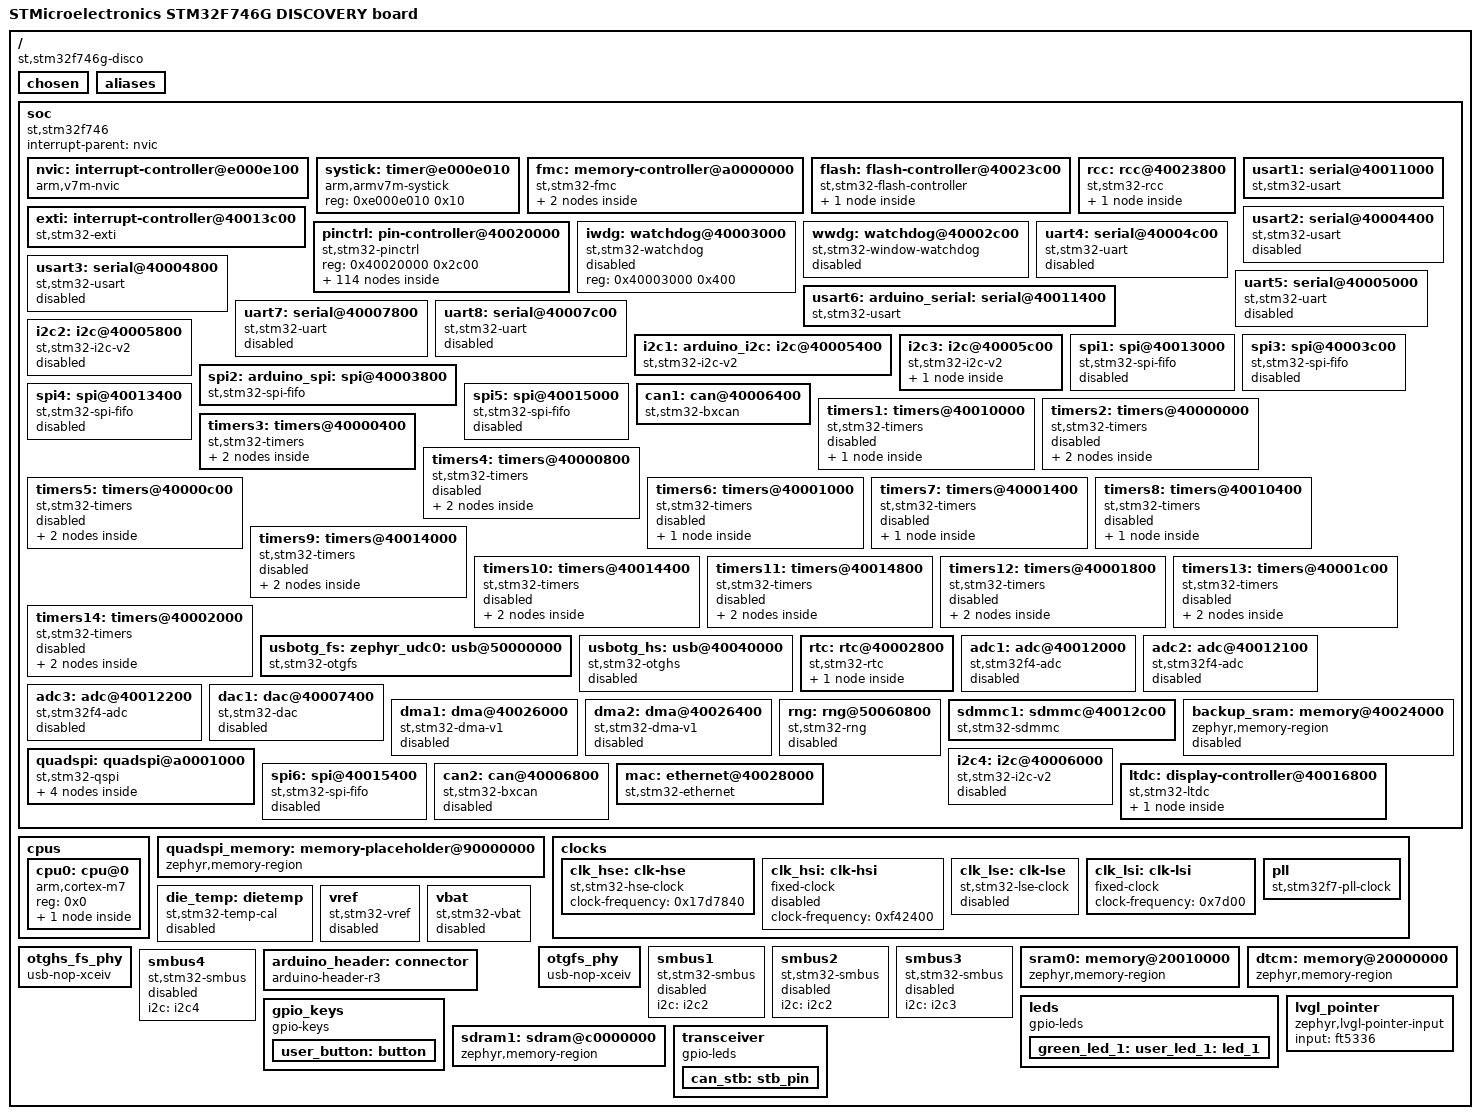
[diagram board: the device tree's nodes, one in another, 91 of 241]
/dts-v1/;

/ {
	#address-cells = < 0x1 >;
	#size-cells = < 0x1 >;
	model = "STMicroelectronics STM32F746G DISCOVERY board";
	compatible = "st,stm32f746g-disco";
	chosen {
		zephyr,entropy = &rng;
		zephyr,flash-controller = &n25q128a1;
		zephyr,console = &usart1;
		zephyr,shell-uart = &usart1;
		zephyr,sram = &sram0;
		zephyr,flash = &flash0;
		zephyr,dtcm = &dtcm;
		zephyr,display = &ltdc;
	};
	aliases {
		led0 = &green_led_1;
		sw0 = &user_button;
		can-primary = &can1;
		led-warn = &user_led_1;
	};
	soc {
		#address-cells = < 0x1 >;
		#size-cells = < 0x1 >;
		compatible = "st,stm32f746", "st,stm32f7", "simple-bus";
		interrupt-parent = < &nvic >;
		ranges;
		nvic: interrupt-controller@e000e100 {
			#address-cells = < 0x1 >;
			compatible = "arm,v7m-nvic";
			reg = < 0xe000e100 0xc00 >;
			interrupt-controller;
			#interrupt-cells = < 0x2 >;
			arm,num-irq-priority-bits = < 0x4 >;
			phandle = < 0x1 >;
		};
		systick: timer@e000e010 {
			compatible = "arm,armv7m-systick";
			reg = < 0xe000e010 0x10 >;
		};
		fmc: memory-controller@a0000000 {
			compatible = "st,stm32-fmc";
			reg = < 0xa0000000 0x400 >;
			clocks = < &rcc 0x38 0x1 >;
			status = "okay";
			pinctrl-0 = < &fmc_nbl0_pe0 &fmc_nbl1_pe1 &fmc_sdclk_pg8 &fmc_sdnwe_ph5 &fmc_sdcke0_pc3 &fmc_sdne0_ph3 &fmc_sdnras_pf11 &fmc_sdncas_pg15 &fmc_a0_pf0 &fmc_a1_pf1 &fmc_a2_pf2 &fmc_a3_pf3 &fmc_a4_pf4 &fmc_a5_pf5 &fmc_a6_pf12 &fmc_a7_pf13 &fmc_a8_pf14 &fmc_a9_pf15 &fmc_a10_pg0 &fmc_a11_pg1 &fmc_a14_pg4 &fmc_a15_pg5 &fmc_d0_pd14 &fmc_d1_pd15 &fmc_d2_pd0 &fmc_d3_pd1 &fmc_d4_pe7 &fmc_d5_pe8 &fmc_d6_pe9 &fmc_d7_pe10 &fmc_d8_pe11 &fmc_d9_pe12 &fmc_d10_pe13 &fmc_d11_pe14 &fmc_d12_pe15 &fmc_d13_pd8 &fmc_d14_pd9 &fmc_d15_pd10 >;
			pinctrl-names = "default";
			sdram: sdram {
				compatible = "st,stm32-fmc-sdram";
				#address-cells = < 0x1 >;
				#size-cells = < 0x0 >;
				status = "okay";
				power-up-delay = < 0x64 >;
				num-auto-refresh = < 0x8 >;
				mode-register = < 0x220 >;
				refresh-rate = < 0x683 >;
				bank@0 {
					reg = < 0x0 >;
					st,sdram-control = < 0x0 0x4 0x10 0x40 0x100 0x800 0x1000 0x0 >;
					st,sdram-timing = < 0x2 0x6 0x4 0x6 0x2 0x2 0x2 >;
				};
			};
		};
		flash: flash-controller@40023c00 {
			compatible = "st,stm32-flash-controller", "st,stm32f7-flash-controller";
			reg = < 0x40023c00 0x400 >;
			interrupts = < 0x4 0x0 >;
			#address-cells = < 0x1 >;
			#size-cells = < 0x1 >;
			flash0: flash@8000000 {
				compatible = "st,stm32-nv-flash", "soc-nv-flash";
				write-block-size = < 0x1 >;
				max-erase-time = < 0xfa0 >;
				reg = < 0x8000000 0x100000 >;
			};
		};
		rcc: rcc@40023800 {
			compatible = "st,stm32-rcc";
			#clock-cells = < 0x2 >;
			reg = < 0x40023800 0x400 >;
			clocks = < &pll >;
			clock-frequency = < 0xcdfe600 >;
			ahb-prescaler = < 0x1 >;
			apb1-prescaler = < 0x4 >;
			apb2-prescaler = < 0x2 >;
			phandle = < 0x2 >;
			rctl: reset-controller {
				compatible = "st,stm32-rcc-rctl";
				#reset-cells = < 0x1 >;
				phandle = < 0x2a >;
			};
		};
		exti: interrupt-controller@40013c00 {
			compatible = "st,stm32-exti";
			interrupt-controller;
			#interrupt-cells = < 0x1 >;
			#address-cells = < 0x1 >;
			reg = < 0x40013c00 0x400 >;
			num-lines = < 0x10 >;
			interrupts = < 0x6 0x0 >, < 0x7 0x0 >, < 0x8 0x0 >, < 0x9 0x0 >, < 0xa 0x0 >, < 0x17 0x0 >, < 0x28 0x0 >;
			interrupt-names = "line0", "line1", "line2", "line3", "line4", "line5-9", "line10-15";
			line-ranges = < 0x0 0x1 >, < 0x1 0x1 >, < 0x2 0x1 >, < 0x3 0x1 >, < 0x4 0x1 >, < 0x5 0x5 >, < 0xa 0x6 >;
		};
		pinctrl: pin-controller@40020000 {
			compatible = "st,stm32-pinctrl";
			#address-cells = < 0x1 >;
			#size-cells = < 0x1 >;
			reg = < 0x40020000 0x2c00 >;
			gpioa: gpio@40020000 {
				compatible = "st,stm32-gpio";
				gpio-controller;
				#gpio-cells = < 0x2 >;
				reg = < 0x40020000 0x400 >;
				clocks = < &rcc 0x30 0x1 >;
				phandle = < 0x37 >;
			};
			gpiob: gpio@40020400 {
				compatible = "st,stm32-gpio";
				gpio-controller;
				#gpio-cells = < 0x2 >;
				reg = < 0x40020400 0x400 >;
				clocks = < &rcc 0x30 0x2 >;
				phandle = < 0x7a >;
			};
			gpioc: gpio@40020800 {
				compatible = "st,stm32-gpio";
				gpio-controller;
				#gpio-cells = < 0x2 >;
				reg = < 0x40020800 0x400 >;
				clocks = < &rcc 0x30 0x4 >;
				phandle = < 0x45 >;
			};
			gpiod: gpio@40020C00 {
				compatible = "st,stm32-gpio";
				gpio-controller;
				#gpio-cells = < 0x2 >;
				reg = < 0x40020c00 0x400 >;
				clocks = < &rcc 0x30 0x8 >;
			};
			gpioe: gpio@40021000 {
				compatible = "st,stm32-gpio";
				gpio-controller;
				#gpio-cells = < 0x2 >;
				reg = < 0x40021000 0x400 >;
				clocks = < &rcc 0x30 0x10 >;
			};
			gpiof: gpio@40021400 {
				compatible = "st,stm32-gpio";
				gpio-controller;
				#gpio-cells = < 0x2 >;
				reg = < 0x40021400 0x400 >;
				clocks = < &rcc 0x30 0x20 >;
				phandle = < 0x78 >;
			};
			gpiog: gpio@40021800 {
				compatible = "st,stm32-gpio";
				gpio-controller;
				#gpio-cells = < 0x2 >;
				reg = < 0x40021800 0x400 >;
				clocks = < &rcc 0x30 0x40 >;
				phandle = < 0x79 >;
			};
			gpioh: gpio@40021C00 {
				compatible = "st,stm32-gpio";
				gpio-controller;
				#gpio-cells = < 0x2 >;
				reg = < 0x40021c00 0x400 >;
				clocks = < &rcc 0x30 0x80 >;
				phandle = < 0x7b >;
			};
			gpioi: gpio@40022000 {
				compatible = "st,stm32-gpio";
				gpio-controller;
				#gpio-cells = < 0x2 >;
				reg = < 0x40022000 0x400 >;
				clocks = < &rcc 0x30 0x100 >;
				phandle = < 0x33 >;
			};
			gpioj: gpio@40022400 {
				compatible = "st,stm32-gpio";
				gpio-controller;
				#gpio-cells = < 0x2 >;
				reg = < 0x40022400 0x400 >;
				clocks = < &rcc 0x30 0x200 >;
			};
			gpiok: gpio@40022800 {
				compatible = "st,stm32-gpio";
				gpio-controller;
				#gpio-cells = < 0x2 >;
				reg = < 0x40022800 0x400 >;
				clocks = < &rcc 0x30 0x400 >;
				phandle = < 0x71 >;
			};
			can1_rx_pb8: can1_rx_pb8 {
				pinmux = < 0x309 >;
				bias-pull-up;
				phandle = < 0x38 >;
			};
			can1_tx_pb9: can1_tx_pb9 {
				pinmux = < 0x329 >;
				phandle = < 0x39 >;
			};
			eth_crs_dv_pa7: eth_crs_dv_pa7 {
				pinmux = < 0xeb >;
				slew-rate = "very-high-speed";
				phandle = < 0x51 >;
			};
			eth_mdc_pc1: eth_mdc_pc1 {
				pinmux = < 0x42b >;
				slew-rate = "very-high-speed";
				phandle = < 0x4c >;
			};
			eth_mdio_pa2: eth_mdio_pa2 {
				pinmux = < 0x4b >;
				slew-rate = "very-high-speed";
				phandle = < 0x50 >;
			};
			eth_ref_clk_pa1: eth_ref_clk_pa1 {
				pinmux = < 0x2b >;
				slew-rate = "very-high-speed";
				phandle = < 0x4f >;
			};
			eth_rxd0_pc4: eth_rxd0_pc4 {
				pinmux = < 0x48b >;
				slew-rate = "very-high-speed";
				phandle = < 0x4d >;
			};
			eth_rxd1_pc5: eth_rxd1_pc5 {
				pinmux = < 0x4ab >;
				slew-rate = "very-high-speed";
				phandle = < 0x4e >;
			};
			eth_txd0_pg13: eth_txd0_pg13 {
				pinmux = < 0xdab >;
				slew-rate = "very-high-speed";
				phandle = < 0x53 >;
			};
			eth_txd1_pg14: eth_txd1_pg14 {
				pinmux = < 0xdcb >;
				slew-rate = "very-high-speed";
				phandle = < 0x54 >;
			};
			eth_tx_en_pg11: eth_tx_en_pg11 {
				pinmux = < 0xd6b >;
				slew-rate = "very-high-speed";
				phandle = < 0x52 >;
			};
			fmc_sdcke0_pc3: fmc_sdcke0_pc3 {
				pinmux = < 0x46c >;
				bias-pull-up;
				slew-rate = "very-high-speed";
				phandle = < 0x7 >;
			};
			fmc_d2_pd0: fmc_d2_pd0 {
				pinmux = < 0x60c >;
				bias-pull-up;
				slew-rate = "very-high-speed";
				phandle = < 0x1b >;
			};
			fmc_d3_pd1: fmc_d3_pd1 {
				pinmux = < 0x62c >;
				bias-pull-up;
				slew-rate = "very-high-speed";
				phandle = < 0x1c >;
			};
			fmc_d13_pd8: fmc_d13_pd8 {
				pinmux = < 0x70c >;
				bias-pull-up;
				slew-rate = "very-high-speed";
				phandle = < 0x26 >;
			};
			fmc_d14_pd9: fmc_d14_pd9 {
				pinmux = < 0x72c >;
				bias-pull-up;
				slew-rate = "very-high-speed";
				phandle = < 0x27 >;
			};
			fmc_d15_pd10: fmc_d15_pd10 {
				pinmux = < 0x74c >;
				bias-pull-up;
				slew-rate = "very-high-speed";
				phandle = < 0x28 >;
			};
			fmc_d0_pd14: fmc_d0_pd14 {
				pinmux = < 0x7cc >;
				bias-pull-up;
				slew-rate = "very-high-speed";
				phandle = < 0x19 >;
			};
			fmc_d1_pd15: fmc_d1_pd15 {
				pinmux = < 0x7ec >;
				bias-pull-up;
				slew-rate = "very-high-speed";
				phandle = < 0x1a >;
			};
			fmc_nbl0_pe0: fmc_nbl0_pe0 {
				pinmux = < 0x80c >;
				bias-pull-up;
				slew-rate = "very-high-speed";
				phandle = < 0x3 >;
			};
			fmc_nbl1_pe1: fmc_nbl1_pe1 {
				pinmux = < 0x82c >;
				bias-pull-up;
				slew-rate = "very-high-speed";
				phandle = < 0x4 >;
			};
			fmc_d4_pe7: fmc_d4_pe7 {
				pinmux = < 0x8ec >;
				bias-pull-up;
				slew-rate = "very-high-speed";
				phandle = < 0x1d >;
			};
			fmc_d5_pe8: fmc_d5_pe8 {
				pinmux = < 0x90c >;
				bias-pull-up;
				slew-rate = "very-high-speed";
				phandle = < 0x1e >;
			};
			fmc_d6_pe9: fmc_d6_pe9 {
				pinmux = < 0x92c >;
				bias-pull-up;
				slew-rate = "very-high-speed";
				phandle = < 0x1f >;
			};
			fmc_d7_pe10: fmc_d7_pe10 {
				pinmux = < 0x94c >;
				bias-pull-up;
				slew-rate = "very-high-speed";
				phandle = < 0x20 >;
			};
			fmc_d8_pe11: fmc_d8_pe11 {
				pinmux = < 0x96c >;
				bias-pull-up;
				slew-rate = "very-high-speed";
				phandle = < 0x21 >;
			};
			fmc_d9_pe12: fmc_d9_pe12 {
				pinmux = < 0x98c >;
				bias-pull-up;
				slew-rate = "very-high-speed";
				phandle = < 0x22 >;
			};
			fmc_d10_pe13: fmc_d10_pe13 {
				pinmux = < 0x9ac >;
				bias-pull-up;
				slew-rate = "very-high-speed";
				phandle = < 0x23 >;
			};
			fmc_d11_pe14: fmc_d11_pe14 {
				pinmux = < 0x9cc >;
				bias-pull-up;
				slew-rate = "very-high-speed";
				phandle = < 0x24 >;
			};
			fmc_d12_pe15: fmc_d12_pe15 {
				pinmux = < 0x9ec >;
				bias-pull-up;
				slew-rate = "very-high-speed";
				phandle = < 0x25 >;
			};
			fmc_a0_pf0: fmc_a0_pf0 {
				pinmux = < 0xa0c >;
				bias-pull-up;
				slew-rate = "very-high-speed";
				phandle = < 0xb >;
			};
			fmc_a1_pf1: fmc_a1_pf1 {
				pinmux = < 0xa2c >;
				bias-pull-up;
				slew-rate = "very-high-speed";
				phandle = < 0xc >;
			};
			fmc_a2_pf2: fmc_a2_pf2 {
				pinmux = < 0xa4c >;
				bias-pull-up;
				slew-rate = "very-high-speed";
				phandle = < 0xd >;
			};
			fmc_a3_pf3: fmc_a3_pf3 {
				pinmux = < 0xa6c >;
				bias-pull-up;
				slew-rate = "very-high-speed";
				phandle = < 0xe >;
			};
			fmc_a4_pf4: fmc_a4_pf4 {
				pinmux = < 0xa8c >;
				bias-pull-up;
				slew-rate = "very-high-speed";
				phandle = < 0xf >;
			};
			fmc_a5_pf5: fmc_a5_pf5 {
				pinmux = < 0xaac >;
				bias-pull-up;
				slew-rate = "very-high-speed";
				phandle = < 0x10 >;
			};
			fmc_sdnras_pf11: fmc_sdnras_pf11 {
				pinmux = < 0xb6c >;
				bias-pull-up;
				slew-rate = "very-high-speed";
				phandle = < 0x9 >;
			};
			fmc_a6_pf12: fmc_a6_pf12 {
				pinmux = < 0xb8c >;
				bias-pull-up;
				slew-rate = "very-high-speed";
				phandle = < 0x11 >;
			};
			fmc_a7_pf13: fmc_a7_pf13 {
				pinmux = < 0xbac >;
				bias-pull-up;
				slew-rate = "very-high-speed";
				phandle = < 0x12 >;
			};
			fmc_a8_pf14: fmc_a8_pf14 {
				pinmux = < 0xbcc >;
				bias-pull-up;
				slew-rate = "very-high-speed";
				phandle = < 0x13 >;
			};
			fmc_a9_pf15: fmc_a9_pf15 {
				pinmux = < 0xbec >;
				bias-pull-up;
				slew-rate = "very-high-speed";
				phandle = < 0x14 >;
			};
			fmc_a10_pg0: fmc_a10_pg0 {
				pinmux = < 0xc0c >;
				bias-pull-up;
				slew-rate = "very-high-speed";
				phandle = < 0x15 >;
			};
			fmc_a11_pg1: fmc_a11_pg1 {
				pinmux = < 0xc2c >;
				bias-pull-up;
				slew-rate = "very-high-speed";
				phandle = < 0x16 >;
			};
			fmc_a14_pg4: fmc_a14_pg4 {
				pinmux = < 0xc8c >;
				bias-pull-up;
				slew-rate = "very-high-speed";
				phandle = < 0x17 >;
			};
			fmc_a15_pg5: fmc_a15_pg5 {
				pinmux = < 0xcac >;
				bias-pull-up;
				slew-rate = "very-high-speed";
				phandle = < 0x18 >;
			};
			fmc_sdclk_pg8: fmc_sdclk_pg8 {
				pinmux = < 0xd0c >;
				bias-pull-up;
				slew-rate = "very-high-speed";
				phandle = < 0x5 >;
			};
			fmc_sdncas_pg15: fmc_sdncas_pg15 {
				pinmux = < 0xdec >;
				bias-pull-up;
				slew-rate = "very-high-speed";
				phandle = < 0xa >;
			};
			fmc_sdne0_ph3: fmc_sdne0_ph3 {
				pinmux = < 0xe6c >;
				bias-pull-up;
				slew-rate = "very-high-speed";
				phandle = < 0x8 >;
			};
			fmc_sdnwe_ph5: fmc_sdnwe_ph5 {
				pinmux = < 0xeac >;
				bias-pull-up;
				slew-rate = "very-high-speed";
				phandle = < 0x6 >;
			};
			i2c1_scl_pb8: i2c1_scl_pb8 {
				pinmux = < 0x304 >;
				bias-pull-up;
				drive-open-drain;
				phandle = < 0x2f >;
			};
			i2c3_scl_ph7: i2c3_scl_ph7 {
				pinmux = < 0xee4 >;
				bias-pull-up;
				drive-open-drain;
				phandle = < 0x31 >;
			};
			i2c1_sda_pb9: i2c1_sda_pb9 {
				pinmux = < 0x324 >;
				bias-pull-up;
				drive-open-drain;
				phandle = < 0x30 >;
			};
			i2c3_sda_ph8: i2c3_sda_ph8 {
				pinmux = < 0xf04 >;
				bias-pull-up;
				drive-open-drain;
				phandle = < 0x32 >;
			};
			ltdc_b0_pe4: ltdc_b0_pe4 {
				pinmux = < 0x88e >;
				phandle = < 0x65 >;
			};
			ltdc_b4_pg12: ltdc_b4_pg12 {
				pinmux = < 0xd89 >;
				phandle = < 0x69 >;
			};
			ltdc_vsync_pi9: ltdc_vsync_pi9 {
				pinmux = < 0x112e >;
				phandle = < 0x70 >;
			};
			ltdc_hsync_pi10: ltdc_hsync_pi10 {
				pinmux = < 0x114e >;
				phandle = < 0x6f >;
			};
			ltdc_clk_pi14: ltdc_clk_pi14 {
				pinmux = < 0x11ce >;
				phandle = < 0x6e >;
			};
			ltdc_r0_pi15: ltdc_r0_pi15 {
				pinmux = < 0x11ee >;
				phandle = < 0x55 >;
			};
			ltdc_r1_pj0: ltdc_r1_pj0 {
				pinmux = < 0x120e >;
				phandle = < 0x56 >;
			};
			ltdc_r2_pj1: ltdc_r2_pj1 {
				pinmux = < 0x122e >;
				phandle = < 0x57 >;
			};
			ltdc_r3_pj2: ltdc_r3_pj2 {
				pinmux = < 0x124e >;
				phandle = < 0x58 >;
			};
			ltdc_r4_pj3: ltdc_r4_pj3 {
				pinmux = < 0x126e >;
				phandle = < 0x59 >;
			};
			ltdc_r5_pj4: ltdc_r5_pj4 {
				pinmux = < 0x128e >;
				phandle = < 0x5a >;
			};
			ltdc_r6_pj5: ltdc_r6_pj5 {
				pinmux = < 0x12ae >;
				phandle = < 0x5b >;
			};
			ltdc_r7_pj6: ltdc_r7_pj6 {
				pinmux = < 0x12ce >;
				phandle = < 0x5c >;
			};
			ltdc_g0_pj7: ltdc_g0_pj7 {
				pinmux = < 0x12ee >;
				phandle = < 0x5d >;
			};
			ltdc_g1_pj8: ltdc_g1_pj8 {
				pinmux = < 0x130e >;
				phandle = < 0x5e >;
			};
			ltdc_g2_pj9: ltdc_g2_pj9 {
				pinmux = < 0x132e >;
				phandle = < 0x5f >;
			};
			ltdc_g3_pj10: ltdc_g3_pj10 {
				pinmux = < 0x134e >;
				phandle = < 0x60 >;
			};
			ltdc_g4_pj11: ltdc_g4_pj11 {
				pinmux = < 0x136e >;
				phandle = < 0x61 >;
			};
			ltdc_b1_pj13: ltdc_b1_pj13 {
				pinmux = < 0x13ae >;
				phandle = < 0x66 >;
			};
			ltdc_b2_pj14: ltdc_b2_pj14 {
				pinmux = < 0x13ce >;
				phandle = < 0x67 >;
			};
			ltdc_b3_pj15: ltdc_b3_pj15 {
				pinmux = < 0x13ee >;
				phandle = < 0x68 >;
			};
			ltdc_g5_pk0: ltdc_g5_pk0 {
				pinmux = < 0x140e >;
				phandle = < 0x62 >;
			};
			ltdc_g6_pk1: ltdc_g6_pk1 {
				pinmux = < 0x142e >;
				phandle = < 0x63 >;
			};
			ltdc_g7_pk2: ltdc_g7_pk2 {
				pinmux = < 0x144e >;
				phandle = < 0x64 >;
			};
			ltdc_b5_pk4: ltdc_b5_pk4 {
				pinmux = < 0x148e >;
				phandle = < 0x6a >;
			};
			ltdc_b6_pk5: ltdc_b6_pk5 {
				pinmux = < 0x14ae >;
				phandle = < 0x6b >;
			};
			ltdc_b7_pk6: ltdc_b7_pk6 {
				pinmux = < 0x14ce >;
				phandle = < 0x6c >;
			};
			ltdc_de_pk7: ltdc_de_pk7 {
				pinmux = < 0x14ee >;
				phandle = < 0x6d >;
			};
			quadspi_clk_pb2: quadspi_clk_pb2 {
				pinmux = < 0x249 >;
				slew-rate = "very-high-speed";
				phandle = < 0x46 >;
			};
			quadspi_bk1_ncs_pb6: quadspi_bk1_ncs_pb6 {
				pinmux = < 0x2ca >;
				slew-rate = "very-high-speed";
				phandle = < 0x47 >;
			};
			quadspi_bk1_io0_pd11: quadspi_bk1_io0_pd11 {
				pinmux = < 0x769 >;
				slew-rate = "very-high-speed";
				phandle = < 0x48 >;
			};
			quadspi_bk1_io1_pd12: quadspi_bk1_io1_pd12 {
				pinmux = < 0x789 >;
				slew-rate = "very-high-speed";
				phandle = < 0x49 >;
			};
			quadspi_bk1_io3_pd13: quadspi_bk1_io3_pd13 {
				pinmux = < 0x7a9 >;
				slew-rate = "very-high-speed";
				phandle = < 0x4b >;
			};
			quadspi_bk1_io2_pe2: quadspi_bk1_io2_pe2 {
				pinmux = < 0x849 >;
				slew-rate = "very-high-speed";
				phandle = < 0x4a >;
			};
			sdmmc1_d0_pc8: sdmmc1_d0_pc8 {
				pinmux = < 0x50c >;
				bias-pull-up;
				slew-rate = "very-high-speed";
				phandle = < 0x3f >;
			};
			sdmmc1_d1_pc9: sdmmc1_d1_pc9 {
				pinmux = < 0x52c >;
				bias-pull-up;
				slew-rate = "very-high-speed";
				phandle = < 0x40 >;
			};
			sdmmc1_d2_pc10: sdmmc1_d2_pc10 {
				pinmux = < 0x54c >;
				bias-pull-up;
				slew-rate = "very-high-speed";
				phandle = < 0x41 >;
			};
			sdmmc1_d3_pc11: sdmmc1_d3_pc11 {
				pinmux = < 0x56c >;
				bias-pull-up;
				slew-rate = "very-high-speed";
				phandle = < 0x42 >;
			};
			sdmmc1_ck_pc12: sdmmc1_ck_pc12 {
				pinmux = < 0x58c >;
				bias-pull-up;
				slew-rate = "very-high-speed";
				phandle = < 0x43 >;
			};
			sdmmc1_cmd_pd2: sdmmc1_cmd_pd2 {
				pinmux = < 0x64c >;
				bias-pull-up;
				slew-rate = "very-high-speed";
				phandle = < 0x44 >;
			};
			spi2_miso_pb14: spi2_miso_pb14 {
				pinmux = < 0x3c5 >;
				bias-pull-down;
				phandle = < 0x35 >;
			};
			spi2_mosi_pb15: spi2_mosi_pb15 {
				pinmux = < 0x3e5 >;
				bias-pull-down;
				phandle = < 0x36 >;
			};
			spi2_sck_pi1: spi2_sck_pi1 {
				pinmux = < 0x1025 >;
				bias-pull-down;
				slew-rate = "very-high-speed";
				phandle = < 0x34 >;
			};
			tim3_ch1_pb4: tim3_ch1_pb4 {
				pinmux = < 0x282 >;
				phandle = < 0x3a >;
			};
			usart1_rx_pb7: usart1_rx_pb7 {
				pinmux = < 0x2e7 >;
				phandle = < 0x2c >;
			};
			usart6_rx_pc7: usart6_rx_pc7 {
				pinmux = < 0x4e8 >;
				phandle = < 0x2e >;
			};
			usart1_tx_pa9: usart1_tx_pa9 {
				pinmux = < 0x127 >;
				bias-pull-up;
				phandle = < 0x2b >;
			};
			usart6_tx_pc6: usart6_tx_pc6 {
				pinmux = < 0x4c8 >;
				bias-pull-up;
				phandle = < 0x2d >;
			};
			usb_otg_fs_dm_pa11: usb_otg_fs_dm_pa11 {
				pinmux = < 0x16a >;
				phandle = < 0x3c >;
			};
			usb_otg_fs_dp_pa12: usb_otg_fs_dp_pa12 {
				pinmux = < 0x18a >;
				phandle = < 0x3d >;
			};
		};
		iwdg: watchdog@40003000 {
			compatible = "st,stm32-watchdog";
			reg = < 0x40003000 0x400 >;
			status = "disabled";
		};
		wwdg: watchdog@40002c00 {
			compatible = "st,stm32-window-watchdog";
			reg = < 0x40002c00 0x400 >;
			clocks = < &rcc 0x40 0x800 >;
			interrupts = < 0x0 0x7 >;
			status = "disabled";
		};
		usart1: serial@40011000 {
			compatible = "st,stm32-usart", "st,stm32-uart";
			reg = < 0x40011000 0x400 >;
			clocks = < &rcc 0x44 0x10 >;
			resets = < &rctl 0x484 >;
			interrupts = < 0x25 0x0 >;
			status = "okay";
			pinctrl-0 = < &usart1_tx_pa9 &usart1_rx_pb7 >;
			pinctrl-names = "default";
			current-speed = < 0x1c200 >;
		};
		usart2: serial@40004400 {
			compatible = "st,stm32-usart", "st,stm32-uart";
			reg = < 0x40004400 0x400 >;
			clocks = < &rcc 0x40 0x20000 >;
			resets = < &rctl 0x411 >;
			interrupts = < 0x26 0x0 >;
			status = "disabled";
		};
		usart3: serial@40004800 {
			compatible = "st,stm32-usart", "st,stm32-uart";
			reg = < 0x40004800 0x400 >;
			clocks = < &rcc 0x40 0x40000 >;
			resets = < &rctl 0x412 >;
			interrupts = < 0x27 0x0 >;
			status = "disabled";
		};
		uart4: serial@40004c00 {
			compatible = "st,stm32-uart";
			reg = < 0x40004c00 0x400 >;
			clocks = < &rcc 0x40 0x80000 >;
			resets = < &rctl 0x413 >;
			interrupts = < 0x34 0x0 >;
			status = "disabled";
		};
		uart5: serial@40005000 {
			compatible = "st,stm32-uart";
			reg = < 0x40005000 0x400 >;
			clocks = < &rcc 0x40 0x100000 >;
			resets = < &rctl 0x414 >;
			interrupts = < 0x35 0x0 >;
			status = "disabled";
		};
		usart6: arduino_serial: serial@40011400 {
			compatible = "st,stm32-usart", "st,stm32-uart";
			reg = < 0x40011400 0x400 >;
			clocks = < &rcc 0x44 0x20 >;
			resets = < &rctl 0x485 >;
			interrupts = < 0x47 0x0 >;
			status = "okay";
			pinctrl-0 = < &usart6_tx_pc6 &usart6_rx_pc7 >;
			pinctrl-names = "default";
			current-speed = < 0x1c200 >;
		};
		uart7: serial@40007800 {
			compatible = "st,stm32-uart";
			reg = < 0x40007800 0x400 >;
			clocks = < &rcc 0x40 0x40000000 >;
			resets = < &rctl 0x41e >;
			interrupts = < 0x52 0x0 >;
			status = "disabled";
		};
		uart8: serial@40007c00 {
			compatible = "st,stm32-uart";
			reg = < 0x40007c00 0x400 >;
			clocks = < &rcc 0x40 0x80000000 >;
			resets = < &rctl 0x41f >;
			interrupts = < 0x53 0x0 >;
			status = "disabled";
		};
		i2c1: arduino_i2c: i2c@40005400 {
			compatible = "st,stm32-i2c-v2";
			clock-frequency = < 0x61a80 >;
			#address-cells = < 0x1 >;
			#size-cells = < 0x0 >;
			reg = < 0x40005400 0x400 >;
			clocks = < &rcc 0x40 0x200000 >;
			interrupts = < 0x1f 0x0 >, < 0x20 0x0 >;
			interrupt-names = "event", "error";
			status = "okay";
			pinctrl-0 = < &i2c1_scl_pb8 &i2c1_sda_pb9 >;
			pinctrl-names = "default";
		};
		i2c2: i2c@40005800 {
			compatible = "st,stm32-i2c-v2";
			clock-frequency = < 0x186a0 >;
			#address-cells = < 0x1 >;
			#size-cells = < 0x0 >;
			reg = < 0x40005800 0x400 >;
			clocks = < &rcc 0x40 0x400000 >;
			interrupts = < 0x21 0x0 >, < 0x22 0x0 >;
			interrupt-names = "event", "error";
			status = "disabled";
			phandle = < 0x75 >;
		};
		i2c3: i2c@40005c00 {
			compatible = "st,stm32-i2c-v2";
			clock-frequency = < 0x61a80 >;
			#address-cells = < 0x1 >;
			#size-cells = < 0x0 >;
			reg = < 0x40005c00 0x400 >;
			clocks = < &rcc 0x40 0x800000 >;
			interrupts = < 0x48 0x0 >, < 0x49 0x0 >;
			interrupt-names = "event", "error";
			status = "okay";
			pinctrl-0 = < &i2c3_scl_ph7 &i2c3_sda_ph8 >;
			pinctrl-names = "default";
			phandle = < 0x76 >;
			ft5336: ft5336@38 {
				compatible = "focaltech,ft5336";
				reg = < 0x38 >;
				int-gpios = < &gpioi 0xd 0x0 >;
				phandle = < 0x7c >;
			};
		};
		spi1: spi@40013000 {
			compatible = "st,stm32-spi-fifo", "st,stm32-spi";
			#address-cells = < 0x1 >;
			#size-cells = < 0x0 >;
			reg = < 0x40013000 0x400 >;
			clocks = < &rcc 0x44 0x1000 >;
			interrupts = < 0x23 0x5 >;
			status = "disabled";
		};
		spi2: arduino_spi: spi@40003800 {
			compatible = "st,stm32-spi-fifo", "st,stm32-spi";
			#address-cells = < 0x1 >;
			#size-cells = < 0x0 >;
			reg = < 0x40003800 0x400 >;
			clocks = < &rcc 0x40 0x4000 >;
			interrupts = < 0x24 0x5 >;
			status = "okay";
			pinctrl-0 = < &spi2_sck_pi1 &spi2_miso_pb14 &spi2_mosi_pb15 >;
			pinctrl-names = "default";
			cs-gpios = < &gpioa 0x8 0x11 >;
		};
		spi3: spi@40003c00 {
			compatible = "st,stm32-spi-fifo", "st,stm32-spi";
			#address-cells = < 0x1 >;
			#size-cells = < 0x0 >;
			reg = < 0x40003c00 0x400 >;
			clocks = < &rcc 0x40 0x8000 >;
			interrupts = < 0x33 0x5 >;
			status = "disabled";
		};
		spi4: spi@40013400 {
			compatible = "st,stm32-spi-fifo", "st,stm32-spi";
			#address-cells = < 0x1 >;
			#size-cells = < 0x0 >;
			reg = < 0x40013400 0x400 >;
			clocks = < &rcc 0x44 0x2000 >;
			interrupts = < 0x54 0x5 >;
			status = "disabled";
		};
		spi5: spi@40015000 {
			compatible = "st,stm32-spi-fifo", "st,stm32-spi";
			#address-cells = < 0x1 >;
			#size-cells = < 0x0 >;
			reg = < 0x40015000 0x400 >;
			clocks = < &rcc 0x44 0x100000 >;
			interrupts = < 0x55 0x5 >;
			status = "disabled";
		};
		can1: can@40006400 {
			compatible = "st,stm32-bxcan";
			reg = < 0x40006400 0x400 >;
			interrupts = < 0x13 0x0 >, < 0x14 0x0 >, < 0x15 0x0 >, < 0x16 0x0 >;
			interrupt-names = "TX", "RX0", "RX1", "SCE";
			clocks = < &rcc 0x40 0x2000000 >;
			status = "okay";
			pinctrl-0 = < &can1_rx_pb8 &can1_tx_pb9 >;
			pinctrl-names = "default";
			bitrate = < 0x7a120 >;
			sample-point = < 0x36b >;
		};
		timers1: timers@40010000 {
			compatible = "st,stm32-timers";
			reg = < 0x40010000 0x400 >;
			clocks = < &rcc 0x44 0x1 >;
			resets = < &rctl 0x480 >;
			interrupts = < 0x18 0x0 >, < 0x19 0x0 >, < 0x1a 0x0 >, < 0x1b 0x0 >;
			interrupt-names = "brk", "up", "trgcom", "cc";
			st,prescaler = < 0x0 >;
			status = "disabled";
			pwm {
				compatible = "st,stm32-pwm";
				status = "disabled";
				#pwm-cells = < 0x3 >;
			};
		};
		timers2: timers@40000000 {
			compatible = "st,stm32-timers";
			reg = < 0x40000000 0x400 >;
			clocks = < &rcc 0x40 0x1 >;
			resets = < &rctl 0x400 >;
			interrupts = < 0x1c 0x0 >;
			interrupt-names = "global";
			st,prescaler = < 0x0 >;
			status = "disabled";
			pwm {
				compatible = "st,stm32-pwm";
				status = "disabled";
				#pwm-cells = < 0x3 >;
			};
			counter {
				compatible = "st,stm32-counter";
				status = "disabled";
			};
		};
		timers3: timers@40000400 {
			compatible = "st,stm32-timers";
			reg = < 0x40000400 0x400 >;
			clocks = < &rcc 0x40 0x2 >;
			resets = < &rctl 0x401 >;
			interrupts = < 0x1d 0x0 >;
			interrupt-names = "global";
			st,prescaler = < 0x2710 >;
			status = "okay";
			pwm3: pwm {
				compatible = "st,stm32-pwm";
				status = "okay";
				#pwm-cells = < 0x3 >;
				pinctrl-0 = < &tim3_ch1_pb4 >;
				pinctrl-names = "default";
			};
			counter {
				compatible = "st,stm32-counter";
				status = "disabled";
			};
		};
		timers4: timers@40000800 {
			compatible = "st,stm32-timers";
			reg = < 0x40000800 0x400 >;
			clocks = < &rcc 0x40 0x4 >;
			resets = < &rctl 0x402 >;
			interrupts = < 0x1e 0x0 >;
			interrupt-names = "global";
			st,prescaler = < 0x0 >;
			status = "disabled";
			pwm {
				compatible = "st,stm32-pwm";
				status = "disabled";
				#pwm-cells = < 0x3 >;
			};
			counter {
				compatible = "st,stm32-counter";
				status = "disabled";
			};
		};
		timers5: timers@40000c00 {
			compatible = "st,stm32-timers";
			reg = < 0x40000c00 0x400 >;
			clocks = < &rcc 0x40 0x8 >;
			resets = < &rctl 0x403 >;
			interrupts = < 0x32 0x0 >;
			interrupt-names = "global";
			st,prescaler = < 0x0 >;
			status = "disabled";
			pwm {
				compatible = "st,stm32-pwm";
				status = "disabled";
				#pwm-cells = < 0x3 >;
			};
			counter {
				compatible = "st,stm32-counter";
				status = "disabled";
			};
		};
		timers6: timers@40001000 {
			compatible = "st,stm32-timers";
			reg = < 0x40001000 0x400 >;
			clocks = < &rcc 0x40 0x10 >;
			resets = < &rctl 0x404 >;
			interrupts = < 0x36 0x0 >;
			interrupt-names = "global";
			st,prescaler = < 0x0 >;
			status = "disabled";
			counter {
				compatible = "st,stm32-counter";
				status = "disabled";
			};
		};
		timers7: timers@40001400 {
			compatible = "st,stm32-timers";
			reg = < 0x40001400 0x400 >;
			clocks = < &rcc 0x40 0x20 >;
			resets = < &rctl 0x405 >;
			interrupts = < 0x37 0x0 >;
			interrupt-names = "global";
			st,prescaler = < 0x0 >;
			status = "disabled";
			counter {
				compatible = "st,stm32-counter";
				status = "disabled";
			};
		};
		timers8: timers@40010400 {
			compatible = "st,stm32-timers";
			reg = < 0x40010400 0x400 >;
			clocks = < &rcc 0x44 0x2 >;
			resets = < &rctl 0x481 >;
			interrupts = < 0x2b 0x0 >, < 0x2c 0x0 >, < 0x2d 0x0 >, < 0x2e 0x0 >;
			interrupt-names = "brk", "up", "trgcom", "cc";
			st,prescaler = < 0x0 >;
			status = "disabled";
			pwm {
				compatible = "st,stm32-pwm";
				status = "disabled";
				#pwm-cells = < 0x3 >;
			};
		};
		timers9: timers@40014000 {
			compatible = "st,stm32-timers";
			reg = < 0x40014000 0x400 >;
			clocks = < &rcc 0x44 0x10000 >;
			resets = < &rctl 0x490 >;
			interrupts = < 0x18 0x0 >;
			interrupt-names = "global";
			st,prescaler = < 0x0 >;
			status = "disabled";
			pwm {
				compatible = "st,stm32-pwm";
				status = "disabled";
				#pwm-cells = < 0x3 >;
			};
			counter {
				compatible = "st,stm32-counter";
				status = "disabled";
			};
		};
		timers10: timers@40014400 {
			compatible = "st,stm32-timers";
			reg = < 0x40014400 0x400 >;
			clocks = < &rcc 0x44 0x20000 >;
			resets = < &rctl 0x491 >;
			interrupts = < 0x19 0x0 >;
			interrupt-names = "global";
			st,prescaler = < 0x0 >;
			status = "disabled";
			pwm {
				compatible = "st,stm32-pwm";
				status = "disabled";
				#pwm-cells = < 0x3 >;
			};
			counter {
				compatible = "st,stm32-counter";
				status = "disabled";
			};
		};
		timers11: timers@40014800 {
			compatible = "st,stm32-timers";
			reg = < 0x40014800 0x400 >;
			clocks = < &rcc 0x44 0x40000 >;
			resets = < &rctl 0x492 >;
			interrupts = < 0x1a 0x0 >;
			interrupt-names = "global";
			st,prescaler = < 0x0 >;
			status = "disabled";
			pwm {
				compatible = "st,stm32-pwm";
				status = "disabled";
				#pwm-cells = < 0x3 >;
			};
			counter {
				compatible = "st,stm32-counter";
				status = "disabled";
			};
		};
		timers12: timers@40001800 {
			compatible = "st,stm32-timers";
			reg = < 0x40001800 0x400 >;
			clocks = < &rcc 0x40 0x40 >;
			resets = < &rctl 0x406 >;
			interrupts = < 0x2b 0x0 >;
			interrupt-names = "global";
			st,prescaler = < 0x0 >;
			status = "disabled";
			pwm {
				compatible = "st,stm32-pwm";
				status = "disabled";
				#pwm-cells = < 0x3 >;
			};
			counter {
				compatible = "st,stm32-counter";
				status = "disabled";
			};
		};
		timers13: timers@40001c00 {
			compatible = "st,stm32-timers";
			reg = < 0x40001c00 0x400 >;
			clocks = < &rcc 0x40 0x80 >;
			resets = < &rctl 0x407 >;
			interrupts = < 0x2c 0x0 >;
			interrupt-names = "global";
			st,prescaler = < 0x0 >;
			status = "disabled";
			pwm {
				compatible = "st,stm32-pwm";
				status = "disabled";
				#pwm-cells = < 0x3 >;
			};
			counter {
				compatible = "st,stm32-counter";
				status = "disabled";
			};
		};
		timers14: timers@40002000 {
			compatible = "st,stm32-timers";
			reg = < 0x40002000 0x400 >;
			clocks = < &rcc 0x40 0x100 >;
			resets = < &rctl 0x408 >;
			interrupts = < 0x2d 0x0 >;
			interrupt-names = "global";
			st,prescaler = < 0x0 >;
			status = "disabled";
			pwm {
				compatible = "st,stm32-pwm";
				status = "disabled";
				#pwm-cells = < 0x3 >;
			};
			counter {
				compatible = "st,stm32-counter";
				status = "disabled";
			};
		};
		usbotg_fs: zephyr_udc0: usb@50000000 {
			compatible = "st,stm32-otgfs";
			reg = < 0x50000000 0x40000 >;
			interrupts = < 0x43 0x0 >;
			interrupt-names = "otgfs";
			num-bidir-endpoints = < 0x6 >;
			ram-size = < 0x500 >;
			maximum-speed = "full-speed";
			phys = < &otgfs_phy >;
			clocks = < &rcc 0x34 0x80 >, < &rcc 0x6 0x3b90 >;
			status = "okay";
			pinctrl-0 = < &usb_otg_fs_dm_pa11 &usb_otg_fs_dp_pa12 >;
			pinctrl-names = "default";
		};
		usbotg_hs: usb@40040000 {
			compatible = "st,stm32-otghs";
			reg = < 0x40040000 0x40000 >;
			interrupts = < 0x4d 0x0 >, < 0x4a 0x0 >, < 0x4b 0x0 >;
			interrupt-names = "otghs", "ep1_out", "ep1_in";
			num-bidir-endpoints = < 0x9 >;
			ram-size = < 0x1000 >;
			maximum-speed = "full-speed";
			clocks = < &rcc 0x30 0x20000000 >, < &rcc 0x6 0x3b90 >;
			phys = < &otghs_fs_phy >;
			status = "disabled";
		};
		rtc: rtc@40002800 {
			compatible = "st,stm32-rtc";
			reg = < 0x40002800 0x300 >;
			interrupts = < 0x29 0x0 >;
			clocks = < &rcc 0x40 0x10000000 >, < &rcc 0x3 0x26870 >;
			prescaler = < 0x8000 >;
			alarms-count = < 0x2 >;
			alrm-exti-line = < 0x11 >;
			status = "okay";
			bbram: backup_regs {
				compatible = "st,stm32-bbram";
				st,backup-regs = < 0x20 >;
				status = "okay";
			};
		};
		adc1: adc@40012000 {
			compatible = "st,stm32f4-adc", "st,stm32-adc";
			reg = < 0x40012000 0x50 >;
			clocks = < &rcc 0x44 0x100 >;
			interrupts = < 0x12 0x0 >;
			status = "disabled";
			#io-channel-cells = < 0x1 >;
			resolutions = < 0x607804 0x517804 0x427804 0x337804 >;
			sampling-times = < 0x3 0xf 0x1c 0x38 0x54 0x70 0x90 0x1e0 >;
			st,adc-clock-source = < 0x1 >;
			st,adc-sequencer = < 0x1 >;
			phandle = < 0x74 >;
		};
		adc2: adc@40012100 {
			compatible = "st,stm32f4-adc", "st,stm32-adc";
			reg = < 0x40012100 0x50 >;
			clocks = < &rcc 0x44 0x200 >;
			interrupts = < 0x12 0x0 >;
			status = "disabled";
			#io-channel-cells = < 0x1 >;
			resolutions = < 0x607804 0x517804 0x427804 0x337804 >;
			sampling-times = < 0x3 0xf 0x1c 0x38 0x54 0x70 0x90 0x1e0 >;
			st,adc-clock-source = < 0x1 >;
			st,adc-sequencer = < 0x1 >;
		};
		adc3: adc@40012200 {
			compatible = "st,stm32f4-adc", "st,stm32-adc";
			reg = < 0x40012200 0x50 >;
			clocks = < &rcc 0x44 0x400 >;
			interrupts = < 0x12 0x0 >;
			status = "disabled";
			#io-channel-cells = < 0x1 >;
			resolutions = < 0x607804 0x517804 0x427804 0x337804 >;
			sampling-times = < 0x3 0xf 0x1c 0x38 0x54 0x70 0x90 0x1e0 >;
			st,adc-clock-source = < 0x1 >;
			st,adc-sequencer = < 0x1 >;
		};
		dac1: dac@40007400 {
			compatible = "st,stm32-dac";
			reg = < 0x40007400 0x400 >;
			clocks = < &rcc 0x40 0x20000000 >;
			status = "disabled";
			#io-channel-cells = < 0x1 >;
		};
		dma1: dma@40026000 {
			compatible = "st,stm32-dma-v1";
			#dma-cells = < 0x4 >;
			reg = < 0x40026000 0x400 >;
			interrupts = < 0xb 0x0 0xc 0x0 0xd 0x0 0xe 0x0 0xf 0x0 0x10 0x0 0x11 0x0 0x2f 0x0 >;
			clocks = < &rcc 0x30 0x200000 >;
			status = "disabled";
		};
		dma2: dma@40026400 {
			compatible = "st,stm32-dma-v1";
			#dma-cells = < 0x4 >;
			reg = < 0x40026400 0x400 >;
			interrupts = < 0x38 0x0 0x39 0x0 0x3a 0x0 0x3b 0x0 0x3c 0x0 0x44 0x0 0x45 0x0 0x46 0x0 >;
			clocks = < &rcc 0x30 0x400000 >;
			st,mem2mem;
			status = "disabled";
		};
		rng: rng@50060800 {
			compatible = "st,stm32-rng";
			reg = < 0x50060800 0x400 >;
			interrupts = < 0x50 0x0 >;
			clocks = < &rcc 0x34 0x40 >, < &rcc 0x6 0x3b90 >;
			status = "disabled";
		};
		sdmmc1: sdmmc@40012c00 {
			compatible = "st,stm32-sdmmc";
			reg = < 0x40012c00 0x400 >;
			clocks = < &rcc 0x44 0x800 >, < &rcc 0x6 0x3c90 >;
			resets = < &rctl 0x48b >;
			interrupts = < 0x31 0x0 >;
			status = "okay";
			pinctrl-0 = < &sdmmc1_d0_pc8 &sdmmc1_d1_pc9 &sdmmc1_d2_pc10 &sdmmc1_d3_pc11 &sdmmc1_ck_pc12 &sdmmc1_cmd_pd2 >;
			pinctrl-names = "default";
			cd-gpios = < &gpioc 0xd 0x1 >;
		};
		backup_sram: memory@40024000 {
			compatible = "zephyr,memory-region", "st,stm32-backup-sram";
			reg = < 0x40024000 0x1000 >;
			clocks = < &rcc 0x30 0x40000 >;
			zephyr,memory-region = "BACKUP_SRAM";
			status = "disabled";
		};
		quadspi: quadspi@a0001000 {
			compatible = "st,stm32-qspi";
			#address-cells = < 0x1 >;
			#size-cells = < 0x0 >;
			reg = < 0xa0001000 0x34 >;
			interrupts = < 0x5c 0x0 >;
			clocks = < &rcc 0x38 0x2 >;
			status = "okay";
			pinctrl-0 = < &quadspi_clk_pb2 &quadspi_bk1_ncs_pb6 &quadspi_bk1_io0_pd11 &quadspi_bk1_io1_pd12 &quadspi_bk1_io2_pe2 &quadspi_bk1_io3_pd13 >;
			pinctrl-names = "default";
			n25q128a1: qspi-nor-flash@90000000 {
				compatible = "st,stm32-qspi-nor";
				reg = < 0x90000000 0x1000000 >;
				qspi-max-frequency = < 0x44aa200 >;
				status = "okay";
				partitions {
					compatible = "fixed-partitions";
					#address-cells = < 0x1 >;
					#size-cells = < 0x1 >;
					slot1_partition: partition@0 {
						label = "image-1";
						reg = < 0x0 0xa0000 >;
					};
					storage_partition: partition@a0000 {
						label = "storage";
						reg = < 0xa0000 0xf00000 >;
					};
				};
			};
		};
		i2c4: i2c@40006000 {
			compatible = "st,stm32-i2c-v2";
			clock-frequency = < 0x186a0 >;
			#address-cells = < 0x1 >;
			#size-cells = < 0x0 >;
			reg = < 0x40006000 0x400 >;
			clocks = < &rcc 0x40 0x1000000 >;
			interrupts = < 0x5f 0x0 >, < 0x60 0x0 >;
			interrupt-names = "event", "error";
			status = "disabled";
			phandle = < 0x77 >;
		};
		spi6: spi@40015400 {
			compatible = "st,stm32-spi-fifo", "st,stm32-spi";
			#address-cells = < 0x1 >;
			#size-cells = < 0x0 >;
			reg = < 0x40015400 0x400 >;
			clocks = < &rcc 0x44 0x200000 >;
			interrupts = < 0x56 0x5 >;
			status = "disabled";
		};
		can2: can@40006800 {
			compatible = "st,stm32-bxcan";
			reg = < 0x40006800 0x400 >;
			interrupts = < 0x3f 0x0 >, < 0x40 0x0 >, < 0x41 0x0 >, < 0x42 0x0 >;
			interrupt-names = "TX", "RX0", "RX1", "SCE";
			clocks = < &rcc 0x40 0x4000000 >;
			status = "disabled";
		};
		mac: ethernet@40028000 {
			compatible = "st,stm32-ethernet";
			reg = < 0x40028000 0x8000 >;
			interrupts = < 0x3d 0x0 >;
			clock-names = "stmmaceth", "mac-clk-tx", "mac-clk-rx", "mac-clk-ptp";
			clocks = < &rcc 0x30 0x2000000 >, < &rcc 0x30 0x4000000 >, < &rcc 0x30 0x8000000 >, < &rcc 0x30 0x10000000 >;
			status = "okay";
			pinctrl-0 = < &eth_mdc_pc1 &eth_rxd0_pc4 &eth_rxd1_pc5 &eth_ref_clk_pa1 &eth_mdio_pa2 &eth_crs_dv_pa7 &eth_tx_en_pg11 &eth_txd0_pg13 &eth_txd1_pg14 >;
			pinctrl-names = "default";
		};
		ltdc: display-controller@40016800 {
			compatible = "st,stm32-ltdc";
			reg = < 0x40016800 0x200 >;
			interrupts = < 0x58 0x0 >, < 0x59 0x0 >;
			interrupt-names = "ltdc", "ltdc_err";
			clocks = < &rcc 0x44 0x4000000 >;
			status = "okay";
			pinctrl-0 = < &ltdc_r0_pi15 &ltdc_r1_pj0 &ltdc_r2_pj1 &ltdc_r3_pj2 &ltdc_r4_pj3 &ltdc_r5_pj4 &ltdc_r6_pj5 &ltdc_r7_pj6 &ltdc_g0_pj7 &ltdc_g1_pj8 &ltdc_g2_pj9 &ltdc_g3_pj10 &ltdc_g4_pj11 &ltdc_g5_pk0 &ltdc_g6_pk1 &ltdc_g7_pk2 &ltdc_b0_pe4 &ltdc_b1_pj13 &ltdc_b2_pj14 &ltdc_b3_pj15 &ltdc_b4_pg12 &ltdc_b5_pk4 &ltdc_b6_pk5 &ltdc_b7_pk6 &ltdc_de_pk7 &ltdc_clk_pi14 &ltdc_hsync_pi10 &ltdc_vsync_pi9 >;
			pinctrl-names = "default";
			disp-on-gpios = < &gpioi 0xc 0x0 >;
			bl-ctrl-gpios = < &gpiok 0x3 0x0 >;
			ext-sdram = < &sdram1 >;
			width = < 0x1e0 >;
			height = < 0x110 >;
			pixel-format = < 0x10 >;
			def-back-color-red = < 0xff >;
			def-back-color-green = < 0xff >;
			def-back-color-blue = < 0xff >;
			display-timings {
				compatible = "zephyr,panel-timing";
				de-active = < 0x0 >;
				pixelclk-active = < 0x0 >;
				hsync-active = < 0x0 >;
				vsync-active = < 0x0 >;
				hsync-len = < 0x1 >;
				vsync-len = < 0xa >;
				hback-porch = < 0x2b >;
				vback-porch = < 0xc >;
				hfront-porch = < 0x8 >;
				vfront-porch = < 0x4 >;
			};
		};
	};
	cpus {
		#address-cells = < 0x1 >;
		#size-cells = < 0x0 >;
		cpu0: cpu@0 {
			device_type = "cpu";
			compatible = "arm,cortex-m7";
			reg = < 0x0 >;
			#address-cells = < 0x1 >;
			#size-cells = < 0x1 >;
			mpu: mpu@e000ed90 {
				compatible = "arm,armv7m-mpu";
				reg = < 0xe000ed90 0x40 >;
			};
		};
	};
	quadspi_memory: memory-placeholder@90000000 {
		compatible = "zephyr,memory-region", "mmio-sram";
		reg = < 0x90000000 0x10000000 >;
		zephyr,memory-region = "QSPI_PLACEHOLDER";
		zephyr,memory-attr = < 0x2000000 >;
	};
	clocks {
		clk_hse: clk-hse {
			#clock-cells = < 0x0 >;
			compatible = "st,stm32-hse-clock";
			status = "okay";
			clock-frequency = < 0x17d7840 >;
			phandle = < 0x73 >;
		};
		clk_hsi: clk-hsi {
			#clock-cells = < 0x0 >;
			compatible = "fixed-clock";
			clock-frequency = < 0xf42400 >;
			status = "disabled";
		};
		clk_lse: clk-lse {
			#clock-cells = < 0x0 >;
			compatible = "st,stm32-lse-clock";
			clock-frequency = < 0x8000 >;
			driving-capability = < 0x0 >;
			status = "disabled";
		};
		clk_lsi: clk-lsi {
			#clock-cells = < 0x0 >;
			compatible = "fixed-clock";
			clock-frequency = < 0x7d00 >;
			status = "okay";
		};
		pll: pll {
			#clock-cells = < 0x0 >;
			compatible = "st,stm32f7-pll-clock";
			status = "okay";
			div-m = < 0x19 >;
			mul-n = < 0x1b0 >;
			div-p = < 0x2 >;
			div-q = < 0x9 >;
			clocks = < &clk_hse >;
			phandle = < 0x29 >;
		};
	};
	die_temp: dietemp {
		compatible = "st,stm32-temp-cal";
		ts-cal1-addr = < 0x1ff0f44c >;
		ts-cal2-addr = < 0x1ff0f44e >;
		ts-cal1-temp = < 0x1e >;
		ts-cal2-temp = < 0x6e >;
		ts-cal-vrefanalog = < 0xce4 >;
		io-channels = < &adc1 0x12 >;
		status = "disabled";
	};
	vref: vref {
		compatible = "st,stm32-vref";
		vrefint-cal-addr = < 0x1ff0f44a >;
		vrefint-cal-mv = < 0xce4 >;
		io-channels = < &adc1 0x11 >;
		status = "disabled";
	};
	vbat: vbat {
		compatible = "st,stm32-vbat";
		ratio = < 0x4 >;
		io-channels = < &adc1 0x12 >;
		status = "disabled";
	};
	otghs_fs_phy: otghs_fs_phy {
		compatible = "usb-nop-xceiv";
		#phy-cells = < 0x0 >;
		phandle = < 0x3e >;
	};
	otgfs_phy: otgfs_phy {
		compatible = "usb-nop-xceiv";
		#phy-cells = < 0x0 >;
		phandle = < 0x3b >;
	};
	smbus1: smbus1 {
		compatible = "st,stm32-smbus";
		#address-cells = < 0x1 >;
		#size-cells = < 0x0 >;
		i2c = < &i2c2 >;
		status = "disabled";
	};
	smbus2: smbus2 {
		compatible = "st,stm32-smbus";
		#address-cells = < 0x1 >;
		#size-cells = < 0x0 >;
		i2c = < &i2c2 >;
		status = "disabled";
	};
	smbus3: smbus3 {
		compatible = "st,stm32-smbus";
		#address-cells = < 0x1 >;
		#size-cells = < 0x0 >;
		i2c = < &i2c3 >;
		status = "disabled";
	};
	sram0: memory@20010000 {
		compatible = "zephyr,memory-region", "mmio-sram";
		reg = < 0x20010000 0x40000 >;
		zephyr,memory-region = "SRAM0";
	};
	dtcm: memory@20000000 {
		compatible = "zephyr,memory-region", "arm,dtcm";
		reg = < 0x20000000 0x10000 >;
		zephyr,memory-region = "DTCM";
	};
	smbus4: smbus4 {
		compatible = "st,stm32-smbus";
		#address-cells = < 0x1 >;
		#size-cells = < 0x0 >;
		i2c = < &i2c4 >;
		status = "disabled";
	};
	arduino_header: connector {
		compatible = "arduino-header-r3";
		#gpio-cells = < 0x2 >;
		gpio-map-mask = < 0xffffffff 0xffffffc0 >;
		gpio-map-pass-thru = < 0x0 0x3f >;
		gpio-map = < 0x0 0x0 &gpioa 0x0 0x0 >, < 0x1 0x0 &gpiof 0xa 0x0 >, < 0x2 0x0 &gpiof 0x9 0x0 >, < 0x3 0x0 &gpiof 0x8 0x0 >, < 0x4 0x0 &gpiof 0x7 0x0 >, < 0x5 0x0 &gpiof 0x6 0x0 >, < 0x6 0x0 &gpioc 0x7 0x0 >, < 0x7 0x0 &gpioc 0x6 0x0 >, < 0x8 0x0 &gpiog 0x6 0x0 >, < 0x9 0x0 &gpiob 0x4 0x0 >, < 0xa 0x0 &gpiog 0x7 0x0 >, < 0xb 0x0 &gpioi 0x0 0x0 >, < 0xc 0x0 &gpioh 0x6 0x0 >, < 0xd 0x0 &gpioi 0x3 0x0 >, < 0xe 0x0 &gpioi 0x2 0x0 >, < 0xf 0x0 &gpioa 0xf 0x0 >, < 0x10 0x0 &gpioa 0x8 0x0 >, < 0x11 0x0 &gpiob 0xf 0x0 >, < 0x12 0x0 &gpiob 0xe 0x0 >, < 0x13 0x0 &gpioi 0x1 0x0 >, < 0x14 0x0 &gpiob 0x9 0x0 >, < 0x15 0x0 &gpiob 0x8 0x0 >;
	};
	leds {
		compatible = "gpio-leds";
		green_led_1: user_led_1: led_1 {
			gpios = < &gpioi 0x1 0x0 >;
			label = "User Warning LED (PI1)";
		};
	};
	gpio_keys {
		compatible = "gpio-keys";
		user_button: button {
			label = "User";
			gpios = < &gpioi 0xb 0x0 >;
			zephyr,code = < 0xb >;
		};
	};
	lvgl_pointer {
		compatible = "zephyr,lvgl-pointer-input";
		input = < &ft5336 >;
	};
	sdram1: sdram@c0000000 {
		compatible = "zephyr,memory-region", "mmio-sram";
		device_type = "memory";
		reg = < 0xc0000000 0x1000000 >;
		zephyr,memory-region = "SDRAM1";
		zephyr,memory-attr = < 0x100000 >;
		phandle = < 0x72 >;
	};
	transceiver {
		compatible = "gpio-leds";
		can_stb: stb_pin {
			gpios = < &gpioi 0x0 0x0 >;
			label = "CAN Transceiver Standby Control (PI0)";
		};
	};
};
